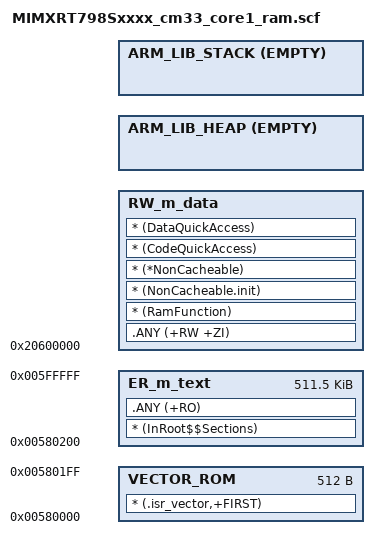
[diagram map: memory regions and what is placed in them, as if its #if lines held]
#!armclang --target=arm-arm-none-eabi -march=armv8-m.main -E -x c
/*
** ###################################################################
**     Processors:          MIMXRT798SGAWAR_cm33_core1
**                          MIMXRT798SGFOA_cm33_core1
**
**     Compiler:            Keil ARM C/C++ Compiler
**     Reference manual:    iMXRT700RM Rev.1, 06/2023
**     Version:             rev. 1.0, 2022-08-01
**     Build:               b231012
**
**     Abstract:
**         Linker file for the Keil ARM C/C++ Compiler
**
**     Copyright 2016 Freescale Semiconductor, Inc.
**     Copyright 2016-2023 NXP
**     SPDX-License-Identifier: BSD-3-Clause
**
**     http:                 www.nxp.com
**     mail:                 support@nxp.com
**
** ###################################################################
*/


/* Sizes */
#if (defined(__stack_size__))
  #define Stack_Size                   __stack_size__
#else
  #define Stack_Size                   0x0400
#endif

#if (defined(__heap_size__))
  #define Heap_Size                    __heap_size__
#else
  #define Heap_Size                    0x0400
#endif


#define  m_interrupts_start            0x00580000
#define  m_interrupts_size             0x00000200

#define  m_text_start                  0x00580200
#define  m_text_size                   0x0007FE00

#define  m_data_start                  0x20600000
#define  m_data_size                   0x00080000

LR_m_text m_text_start m_text_size {   ; load region size_region
  ER_m_text m_text_start m_text_size { ; load address = execution address
    * (InRoot$$Sections)
    .ANY (+RO)
  }

  RW_m_data m_data_start m_data_size-Stack_Size-Heap_Size { ; RW data
    .ANY (+RW +ZI)
    * (RamFunction)
    * (NonCacheable.init)
    * (*NonCacheable)
    * (CodeQuickAccess)
    * (DataQuickAccess)
  }
  ARM_LIB_HEAP +0 EMPTY Heap_Size {    ; Heap region growing up
  }
  ARM_LIB_STACK m_data_start+m_data_size EMPTY -Stack_Size { ; Stack region growing down
  }
}

LR_m_interrupts m_interrupts_start m_interrupts_size {
  VECTOR_ROM m_interrupts_start m_interrupts_size {
    * (.isr_vector,+FIRST)
  }
}
